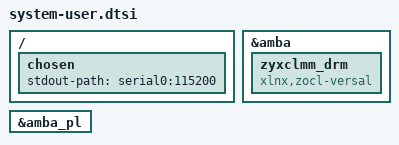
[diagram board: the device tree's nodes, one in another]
/include/ "system-conf.dtsi"
/ {
        chosen {
                stdout-path = "serial0:115200";
        };
};

&amba {
        zyxclmm_drm {
                compatible = "xlnx,zocl-versal";
        };
};
&amba_pl {
	/delete-node/ gpio@a4000000;
};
